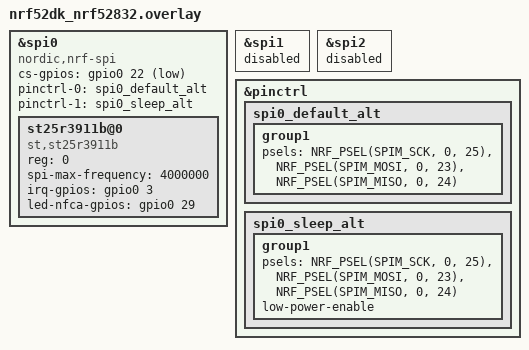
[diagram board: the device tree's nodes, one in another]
&spi0 {
	compatible = "nordic,nrf-spi";
	status = "okay";
	cs-gpios = <&gpio0 22 GPIO_ACTIVE_LOW>;

	pinctrl-0 = <&spi0_default_alt>;
	pinctrl-1 = <&spi0_sleep_alt>;
	pinctrl-names = "default", "sleep";
	st25r3911b@0 {
		compatible = "st,st25r3911b";
		reg = <0>;
		spi-max-frequency = <4000000>;
		irq-gpios = <&gpio0 3 GPIO_ACTIVE_HIGH>;
		led-nfca-gpios = <&gpio0 29 GPIO_ACTIVE_HIGH>;
	};
};

&spi1 {
	status = "disabled";
};

&spi2 {
	status = "disabled";
};

&pinctrl {
	spi0_default_alt: spi0_default_alt {
		group1 {
			psels = <NRF_PSEL(SPIM_SCK, 0, 25)>,
				<NRF_PSEL(SPIM_MOSI, 0, 23)>,
				<NRF_PSEL(SPIM_MISO, 0, 24)>;
		};
	};

	spi0_sleep_alt: spi0_sleep_alt {
		group1 {
			psels = <NRF_PSEL(SPIM_SCK, 0, 25)>,
				<NRF_PSEL(SPIM_MOSI, 0, 23)>,
				<NRF_PSEL(SPIM_MISO, 0, 24)>;
			low-power-enable;
		};
	};
};
